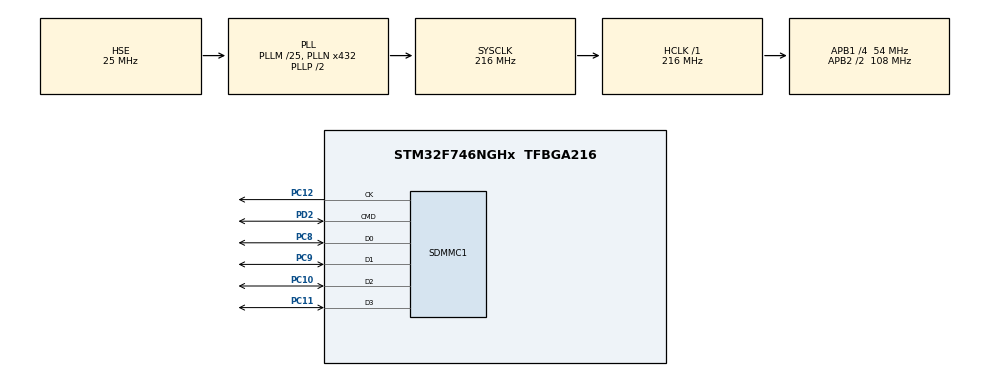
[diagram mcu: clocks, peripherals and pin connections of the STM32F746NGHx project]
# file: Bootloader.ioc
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Mcu.Family=STM32F7
RCC.PLLSourceVirtual=RCC_PLLSOURCE_HSE
RCC.CortexFreq_Value=216000000
PC10.Signal=SDMMC1_D2
PC11.Signal=SDMMC1_D3
PC12.Signal=SDMMC1_CK
PC8.Signal=SDMMC1_D0
PC10.Mode=mmc_4_bits_Wide_bus
RCC.APB1CLKDivider=RCC_HCLK_DIV4
RCC.SYSCLKSource=RCC_SYSCLKSOURCE_PLLCLK
ProjectManager.StackSize=0x400
ProjectManager.TargetToolchain=SW4STM32
PH0/OSC_IN.Mode=HSE-External-Oscillator
RCC.HCLKFreq_Value=216000000
RCC.APB2TimFreq_Value=216000000
PH1/OSC_OUT.Signal=RCC_OSC_OUT
RCC.USBFreq_Value=48000000
RCC.LSE_VALUE=32768
RCC.AHBFreq_Value=216000000
VP_FATFS_VS_Generic.Mode=User_defined
PD2.Mode=mmc_4_bits_Wide_bus
RCC.HSE_VALUE=25000000
PC12.Mode=mmc_4_bits_Wide_bus
board=custom
RCC.VCOOutputFreq_Value=432000000
PH0/OSC_IN.Signal=RCC_OSC_IN
RCC.APB2Freq_Value=108000000
PC9.Mode=mmc_4_bits_Wide_bus
PH1/OSC_OUT.Mode=HSE-External-Oscillator
Mcu.Name=STM32F746NGHx
PC8.Mode=mmc_4_bits_Wide_bus
RCC.SYSCLKFreq_VALUE=216000000
Mcu.Package=TFBGA216
RCC.SDMMCClockSelection=RCC_SDMMC1CLKSOURCE_CLK48
ProjectManager.HeapSize=0x200
PC11.Mode=mmc_4_bits_Wide_bus
RCC.HSI_VALUE=16000000
RCC.PLLQ=9
NVIC.PriorityGroup=NVIC_PRIORITYGROUP_4
FATFS._FS_MINIMIZE=1
FATFS._FS_LOCK=0
RCC.APB2CLKDivider=RCC_HCLK_DIV2
RCC.PLLM=25
RCC.PLLN=432
RCC.APB1TimFreq_Value=108000000
FATFS._FS_READONLY=1
PC9.Signal=SDMMC1_D1
PD2.Signal=SDMMC1_CMD
RCC.APB1Freq_Value=54000000

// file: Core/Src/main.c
/* USER CODE BEGIN Header */
/**
  ******************************************************************************
  * @file           : main.c
  * @brief          : Main program body
  ******************************************************************************
  * @attention
  *
  * <h2><center>&copy; Copyright (c) 2020 STMicroelectronics.
  * All rights reserved.</center></h2>
  *
  * This software component is licensed by ST under Ultimate Liberty license
  * SLA0044, the "License"; You may not use this file except in compliance with
  * the License. You may obtain a copy of the License at:
  *                             www.st.com/SLA0044
  *
  ******************************************************************************
  */
/* USER CODE END Header */
#include "main.h"
#include "fatfs.h"
#include "bootloader.h"

MMC_HandleTypeDef hmmc1;

/* USER CODE BEGIN PV */
char SD_Path[4]; /* SD logical drive path */
SD_HandleTypeDef hsd1;
/* USER CODE END PV */

void SystemClock_Config(void);
static void MX_GPIO_Init(void);
static void MX_SDMMC1_MMC_Init(void);

int main(void)
{
  /* USER CODE BEGIN 1 */
unsigned char resultado;
  /* USER CODE END 1 */

  /* MCU Configuration--------------------------------------------------------*/

  /* Reset of all peripherals, Initializes the Flash interface and the Systick. */
  HAL_Init();

  /* Configure the system clock */
  HAL_RCC_DeInit();
  SystemClock_Config();

  /* Initialize all configured peripherals */
  MX_GPIO_Init();
  MX_SDMMC1_MMC_Init();
  //MX_FATFS_Init();
  /* USER CODE BEGIN 2 */
  resultado = FATFS_LinkDriver(&SD_Driver, SD_Path);
  if(resultado == 0){
	  FRESULT res = FR_DISK_ERR;
	  while (res != FR_OK){
		  res = f_mount(&SDFatFS, SDPath, 1);
	  }
	  if (res == FR_OK){
	  		bootloader();
	  }
  }
  /* USER CODE END 2 */

  /* Infinite loop */
  while (1)
  {

  }
}

void SystemClock_Config(void)
{
  RCC_OscInitTypeDef RCC_OscInitStruct = {0};
  RCC_ClkInitTypeDef RCC_ClkInitStruct = {0};
  RCC_PeriphCLKInitTypeDef PeriphClkInitStruct = {0};

  /** Configure the main internal regulator output voltage
  */
  __HAL_RCC_PWR_CLK_ENABLE();
  __HAL_PWR_VOLTAGESCALING_CONFIG(PWR_REGULATOR_VOLTAGE_SCALE1);
  /** Initializes the RCC Oscillators according to the specified parameters
  * in the RCC_OscInitTypeDef structure.
  */
  RCC_OscInitStruct.OscillatorType = RCC_OSCILLATORTYPE_HSE;
  RCC_OscInitStruct.HSEState = RCC_HSE_ON;
  RCC_OscInitStruct.PLL.PLLState = RCC_PLL_ON;
  RCC_OscInitStruct.PLL.PLLSource = RCC_PLLSOURCE_HSE;
  RCC_OscInitStruct.PLL.PLLM = 25;
  RCC_OscInitStruct.PLL.PLLN = 432;
  RCC_OscInitStruct.PLL.PLLP = RCC_PLLP_DIV2;
  RCC_OscInitStruct.PLL.PLLQ = 9;
  if (HAL_RCC_OscConfig(&RCC_OscInitStruct) != HAL_OK)
  {
    Error_Handler();
  }
  /** Activate the Over-Drive mode
  */
  if (HAL_PWREx_EnableOverDrive() != HAL_OK)
  {
    Error_Handler();
  }
  /** Initializes the CPU, AHB and APB buses clocks
  */
  RCC_ClkInitStruct.ClockType = RCC_CLOCKTYPE_HCLK|RCC_CLOCKTYPE_SYSCLK
                              |RCC_CLOCKTYPE_PCLK1|RCC_CLOCKTYPE_PCLK2;
  RCC_ClkInitStruct.SYSCLKSource = RCC_SYSCLKSOURCE_PLLCLK;
  RCC_ClkInitStruct.AHBCLKDivider = RCC_SYSCLK_DIV1;
  RCC_ClkInitStruct.APB1CLKDivider = RCC_HCLK_DIV4;
  RCC_ClkInitStruct.APB2CLKDivider = RCC_HCLK_DIV2;

  if (HAL_RCC_ClockConfig(&RCC_ClkInitStruct, FLASH_LATENCY_7) != HAL_OK)
  {
    Error_Handler();
  }
  PeriphClkInitStruct.PeriphClockSelection = RCC_PERIPHCLK_SDMMC1|RCC_PERIPHCLK_CLK48;
  PeriphClkInitStruct.Clk48ClockSelection = RCC_CLK48SOURCE_PLL;
  PeriphClkInitStruct.Sdmmc1ClockSelection = RCC_SDMMC1CLKSOURCE_CLK48;
  if (HAL_RCCEx_PeriphCLKConfig(&PeriphClkInitStruct) != HAL_OK)
  {
    Error_Handler();
  }
}

static void MX_SDMMC1_MMC_Init(void)
{

  hsd1.Instance = SDMMC1;
  hsd1.Init.ClockEdge = SDMMC_CLOCK_EDGE_RISING;
  hsd1.Init.ClockBypass = SDMMC_CLOCK_BYPASS_DISABLE;
  hsd1.Init.ClockPowerSave = SDMMC_CLOCK_POWER_SAVE_DISABLE;
  hsd1.Init.BusWide = SDMMC_BUS_WIDE_1B;
  hsd1.Init.HardwareFlowControl = SDMMC_HARDWARE_FLOW_CONTROL_DISABLE;
  hsd1.Init.ClockDiv = 0;
#if 0
  if (HAL_MMC_Init(&hmmc1) != HAL_OK)
  {
    Error_Handler();
  }
  if (HAL_MMC_ConfigWideBusOperation(&hmmc1, SDMMC_BUS_WIDE_4B) != HAL_OK)
  {
    Error_Handler();
  }
#endif

}

static void MX_GPIO_Init(void)
{

  /* GPIO Ports Clock Enable */
  __HAL_RCC_GPIOC_CLK_ENABLE();
  __HAL_RCC_GPIOD_CLK_ENABLE();
  __HAL_RCC_GPIOH_CLK_ENABLE();

}

void Error_Handler(void)
{
  /* USER CODE BEGIN Error_Handler_Debug */
  /* User can add his own implementation to report the HAL error return state */
	Reset_Handler();
  /* USER CODE END Error_Handler_Debug */
}

/************************ (C) COPYRIGHT STMicroelectronics *****END OF FILE****/
